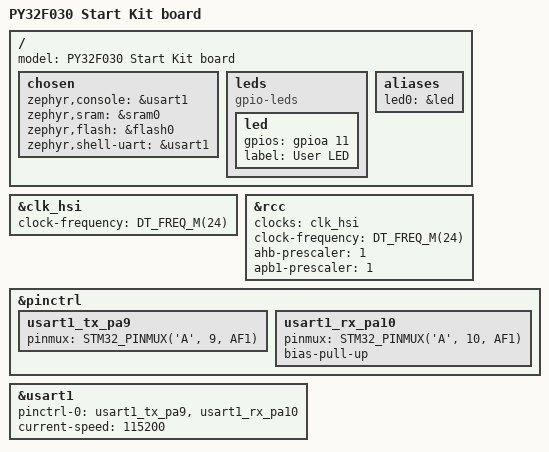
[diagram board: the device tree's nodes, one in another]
/*
 * Copyright (c) 2019 Antony Pavlov <antonynpavlov@gmail.com>
 *
 * SPDX-License-Identifier: Apache-2.0
 */

/dts-v1/;
#include <puya/f0/py32f030X6.dtsi>
#include <zephyr/dt-bindings/pinctrl/stm32-pinctrl.h>

/ {
	model = "PY32F030 Start Kit board";

	chosen {
		zephyr,console = &usart1;
		zephyr,sram = &sram0;
		zephyr,flash = &flash0;
		zephyr,shell-uart = &usart1;
	};

	leds {
		compatible = "gpio-leds";

		led: led {
			gpios = <&gpioa 11 GPIO_ACTIVE_HIGH>;
			label = "User LED";
		};
	};

	aliases {
		led0 = &led;
	};
};

&clk_hsi {
	clock-frequency = <DT_FREQ_M(24)>;
	status = "okay";
};

&rcc {
	clocks = <&clk_hsi>;
	clock-frequency = <DT_FREQ_M(24)>;
	ahb-prescaler = <1>;
	apb1-prescaler = <1>;
};

&pinctrl {
	usart1_tx_pa9: usart1_tx_pa9 {
		pinmux = <STM32_PINMUX('A', 9, AF1)>;
	};

	usart1_rx_pa10: usart1_rx_pa10 {
		pinmux = <STM32_PINMUX('A', 10, AF1)>;
		bias-pull-up;
	};
};

&usart1 {
	pinctrl-0 = <&usart1_tx_pa9 &usart1_rx_pa10>;
	pinctrl-names = "default";
	current-speed = <115200>;
	status = "okay";
};
